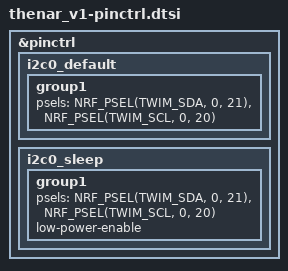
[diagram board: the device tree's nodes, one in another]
// SPDX-License-Identifier: MIT
//
// Pin selections below are STARTING POINTS - they match the placeholder
// MS88SF3 pad-to-net mapping in v1/ergogen/config.yaml. Update both
// files together once the datasheet-derived final pad assignments are
// settled.

#include <nordic/nrf52840_qiaa-pinctrl.dtsi>

&pinctrl {
    i2c0_default: i2c0_default {
        group1 {
            psels = <NRF_PSEL(TWIM_SDA, 0, 21)>,
                    <NRF_PSEL(TWIM_SCL, 0, 20)>;
        };
    };

    i2c0_sleep: i2c0_sleep {
        group1 {
            psels = <NRF_PSEL(TWIM_SDA, 0, 21)>,
                    <NRF_PSEL(TWIM_SCL, 0, 20)>;
            low-power-enable;
        };
    };
};
